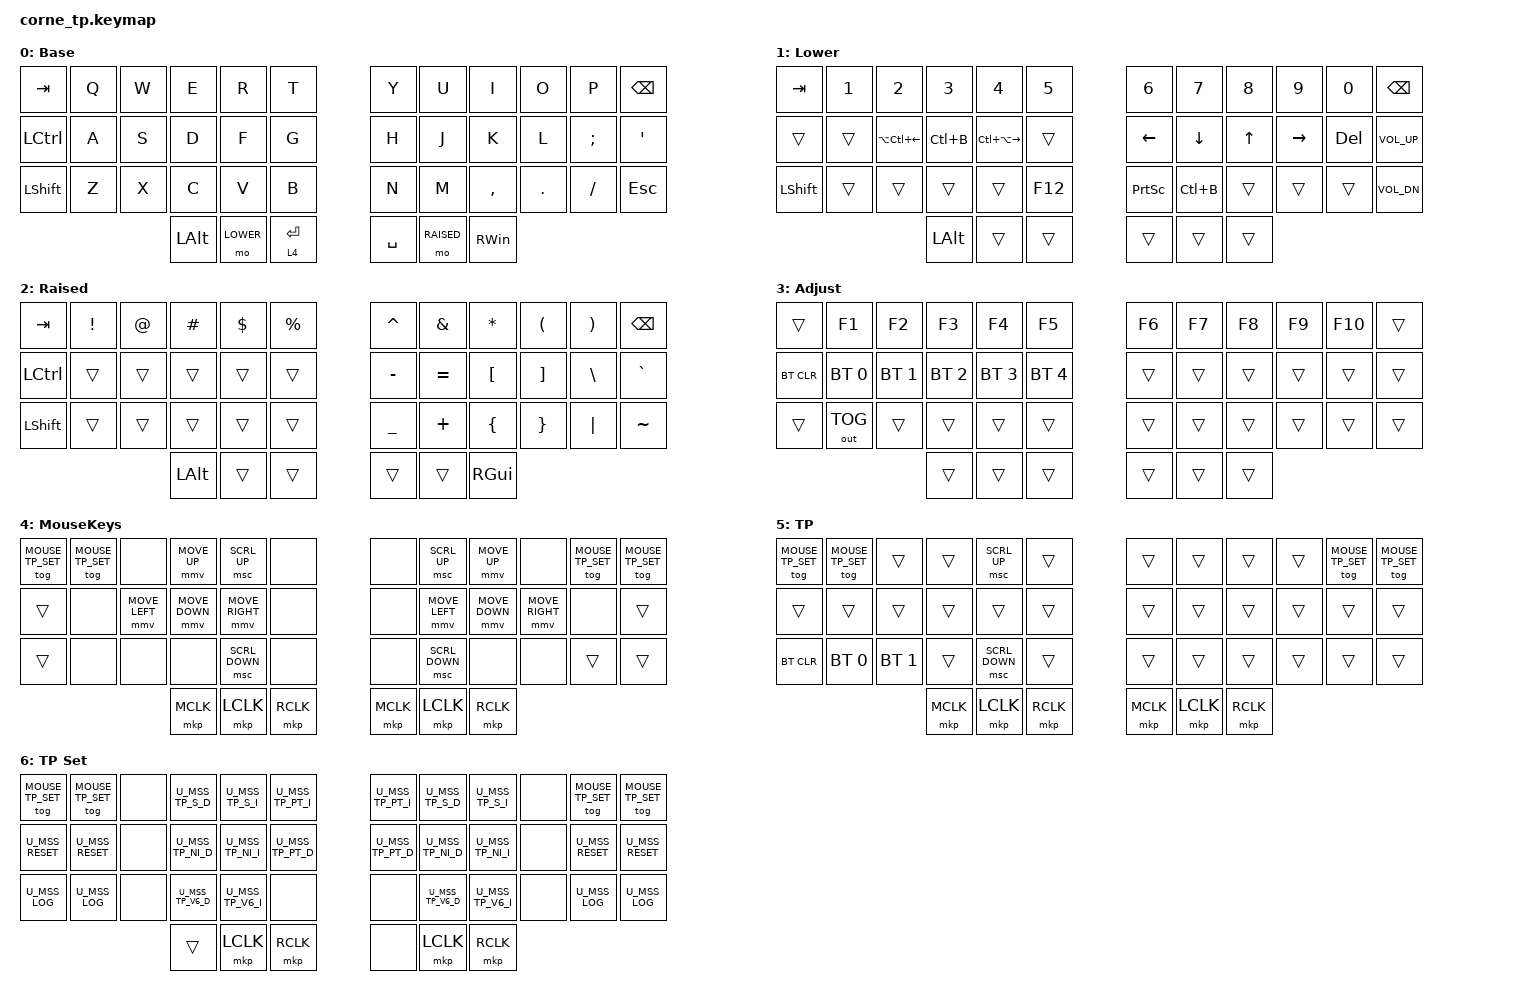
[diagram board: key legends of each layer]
/*
 * Copyright (c) 2020 The ZMK Contributors
 *
 * SPDX-License-Identifier: MIT
 */

#include <behaviors.dtsi>
#include <dt-bindings/zmk/keys.h>
#include <dt-bindings/zmk/bt.h>
#include <dt-bindings/zmk/outputs.h>

#define BASE 0
#define LOWER 1
#define RAISED 2
#define ADJUST 3
#define MOUSE_KEYS 4
#define MOUSE_TP 5
#define MOUSE_TP_SET 6

/*
 * Defines to enable/disable features
 */

#define HAS_MOUSE_KEYS
#define HAS_MOUSE_TP

#ifdef HAS_MOUSE_KEYS
  #include <dt-bindings/zmk/mouse.h>
  #include <behaviors/mouse_keys.dtsi>
#endif  // HAS_MOUSE_KEYS

#ifdef HAS_MOUSE_TP
  #include "include/mouse_tp.dtsi"
#endif  // HAS_MOUSE_TP

// Layer key defines
#ifdef HAS_MOUSE_KEYS
  #define U_THUMB_INNER &mo MOUSE_KEYS
#else
  #define U_THUMB_INNER &none
#endif

#ifdef HAS_MOUSE_TP
  #define U_TOG_TP_SET &tog MOUSE_TP_SET
#else
  #define U_TOG_TP_SET &none
#endif

/ {
    combos {
        compatible = "zmk,combos";
        AdjustLayer {
            bindings = <&mo 4>;
            key-positions = <37 40>;
        };
    };

    keymap {
        compatible = "zmk,keymap";

        Base_layer {
            display-name = "Base";
            bindings = <
// ╭────────────────────────┬────────────────────────┬────────────────────────┬────────────────────────┬────────────────────────┬────────────────────────╮    ╭────────────────────────┬────────────────────────┬────────────────────────┬────────────────────────┬────────────────────────┬────────────────────────╮
             &kp TAB          &kp Q                  &kp W                    &kp E                    &kp R                    &kp T                         &kp Y                    &kp U                    &kp I                    &kp O                    &kp P                    &kp BSPC
// ├────────────────────────┼────────────────────────┼────────────────────────┼────────────────────────┼────────────────────────┼────────────────────────┤    ├────────────────────────┼────────────────────────┼────────────────────────┼────────────────────────┼────────────────────────┼────────────────────────┤
             &kp LCTRL        &kp A                  &kp S                    &kp D                    &kp F                    &kp G                         &kp H                    &kp J                    &kp K                    &kp L                    &kp SEMI                 &kp SQT
// ├────────────────────────┼────────────────────────┼────────────────────────┼────────────────────────┼────────────────────────┼────────────────────────┤    ├────────────────────────┼────────────────────────┼────────────────────────┼────────────────────────┼────────────────────────┼────────────────────────┤
             &kp LSHFT        &kp Z                  &kp X                    &kp C                    &kp V                    &kp B                         &kp N                    &kp M                    &kp COMMA                &kp DOT                  &kp SLASH                &kp ESC
// ╰────────────────────────┴────────────────────────┴────────────────────────┴────────────────────────┼────────────────────────┼────────────────────────┤    ├────────────────────────┼────────────────────────┼────────────────────────┼────────────────────────┼────────────────────────┼────────────────────────╯
                                                                                  &kp LALT               &mo LOWER                &lt 4 RET                      &kp SPACE                &mo RAISED               &kp RIGHT_WIN
//                                                                              ╰────────────────────────┴────────────────────────┴────────────────────────╯    ╰────────────────────────┴────────────────────────┴────────────────────────╯
            >;
        };

        lower_layer {
            display-name = "Lower";
            bindings = <
                &kp TAB    &kp N1    &kp N2            &kp N3      &kp N4            &kp N5        &kp N6     &kp N7     &kp N8     &kp N9     &kp N0     &kp BSPC
                &trans     &trans    &kp LA(LC(LEFT))  &kp LC(B)   &kp LC(LA(RIGHT))  &trans        &kp LEFT   &kp DOWN   &kp UP     &kp RIGHT  &kp DEL    &kp C_VOL_UP
                &kp LSHFT  &trans    &trans            &trans      &trans            &kp F12       &kp PSCRN  &kp LC(B)  &trans     &trans     &trans     &kp C_VOL_DN
                                            &kp LALT   &trans      &trans            &trans        &trans     &trans
            >;
        };

        raise_layer {
            display-name = "Raised";
            bindings = <
                &kp TAB    &kp EXCL    &kp AT     &kp HASH  &kp DLLR  &kp PRCNT    &kp CARET  &kp AMPS   &kp ASTRK  &kp LPAR  &kp RPAR  &kp BSPC
                &kp LCTRL  &trans      &trans     &trans    &trans    &trans       &kp MINUS  &kp EQUAL  &kp LBKT   &kp RBKT  &kp BSLH  &kp GRAVE
                &kp LSHFT  &trans      &trans     &trans    &trans    &trans       &kp UNDER  &kp PLUS   &kp LBRC   &kp RBRC  &kp PIPE  &kp TILDE
                                       &kp LALT   &trans    &trans    &trans       &trans     &kp RGUI
            >;
        };

        Adjust {
            display-name = "Adjust";
            bindings = <
                &trans   &kp F1    &kp F2   &kp F3   &kp F4   &kp F5   &kp F6   &kp F7   &kp F8   &kp F9   &kp F10  &trans
                &bt BT_CLR     &bt BT_SEL 0  &bt BT_SEL 1  &bt BT_SEL 2  &bt BT_SEL 3  &bt BT_SEL 4  &trans  &trans  &trans  &trans  &trans  &trans
                &trans         &out OUT_TOG  &trans        &trans        &trans        &trans        &trans  &trans  &trans  &trans  &trans  &trans
                                               &trans      &trans        &trans        &trans        &trans  &trans
            >;
        };

#ifdef HAS_MOUSE_KEYS
        MouseKeys_layer {
            display-name = "MouseKeys";
            bindings = <
                U_TOG_TP_SET  U_TOG_TP_SET  &none  &mmv MOVE_UP  &msc SCRL_UP  &none   &none   &msc SCRL_UP  &mmv MOVE_UP  &none  U_TOG_TP_SET  U_TOG_TP_SET
                &trans        &none         &mmv MOVE_LEFT  &mmv MOVE_DOWN  &mmv MOVE_RIGHT  &none   &none   &mmv MOVE_LEFT  &mmv MOVE_DOWN  &mmv MOVE_RIGHT  &none  &trans
                &trans        &none         &none          &none           &msc SCRL_DOWN   &none   &none   &msc SCRL_DOWN  &none  &none  &trans  &trans
                                          &mkp MCLK  &mkp LCLK  &mkp RCLK  &mkp MCLK  &mkp LCLK  &mkp RCLK
            >;
        };
#endif

#ifdef HAS_MOUSE_TP
        MouseTP_layer {
            display-name = "TP";
            bindings = <
                U_TOG_TP_SET  U_TOG_TP_SET  &trans  &trans  &msc SCRL_UP  &trans   &trans   &trans  &trans  &trans  U_TOG_TP_SET  U_TOG_TP_SET
                &trans        &trans        &trans  &trans  &trans        &trans   &trans   &trans  &trans  &trans  &trans  &trans
                &bt BT_CLR     &bt BT_SEL 0  &bt BT_SEL 1  &trans  &msc SCRL_DOWN  &trans  &trans   &trans  &trans  &trans  &trans  &trans
                                          &mkp MCLK  &mkp LCLK  &mkp RCLK  &mkp MCLK  &mkp LCLK  &mkp RCLK
            >;
        };

        MouseSettings_layer {
            display-name = "TP Set";
            bindings = <
                U_TOG_TP_SET  U_TOG_TP_SET  &none  U_MSS_TP_S_D  U_MSS_TP_S_I  U_MSS_TP_PT_I  U_MSS_TP_PT_I  U_MSS_TP_S_D  U_MSS_TP_S_I  &none  U_TOG_TP_SET  U_TOG_TP_SET
                U_MSS_RESET   U_MSS_RESET   &none  U_MSS_TP_NI_D  U_MSS_TP_NI_I  U_MSS_TP_PT_D  U_MSS_TP_PT_D  U_MSS_TP_NI_D  U_MSS_TP_NI_I  &none  U_MSS_RESET  U_MSS_RESET
                U_MSS_LOG     U_MSS_LOG     &none  U_MSS_TP_V6_D  U_MSS_TP_V6_I  &none          &none          U_MSS_TP_V6_D  U_MSS_TP_V6_I  &none  U_MSS_LOG   U_MSS_LOG
                                           &trans  &mkp LCLK      &mkp RCLK     &none         &mkp LCLK      &mkp RCLK
            >;
        };
#endif
    };
};
